# SCR_TC3xx register map
Vendor: Infineon; File version: 1.0
Registers are 8-bit, read-write, reset 0x0 unless marked. A register's access mark holds for its fields unless they carry their own. Offsets are from the block's base; [hi:lo] are bit positions; <NAME> marks a mode.

## SCR_UART — SCR Universal asynchronous receiver/transmitter (with LIN support)
Base 0x00040000
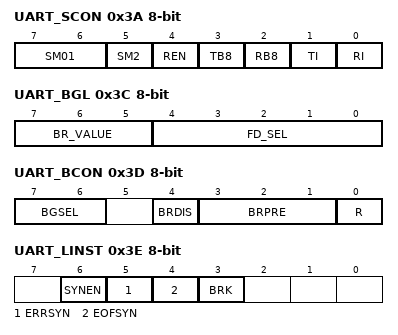
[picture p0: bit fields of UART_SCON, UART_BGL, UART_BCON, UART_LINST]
0x3A UART_SCON — Serial Channel Control Register (SFR 0xBA, RMAP 0)
  [7:6] SM01 — Serial Port Operating Mode Selection. Note:The operating mode of the UART must not be changed while bit REN is set or while a transmission is in progress. Before changing the mode of the UART, make sure that no transmissions are in progress, and that bit REN is cleared to 0. [rw]
    0=MODE_0 (8-bit shift register, fixed baud rate (fPCLK/2)); 1=MODE_1 (8-bit UART, variable baud rate); 2=MODE_2 (9-bit UART, fixed baud rate (fPCLK/64 or fPCLK/32)); 3=MODE_3 (9-bit UART, variable baud rate)
  [5] SM2 — Enable Serial Port Multiprocessor Communication in Modes 2 and 3. In mode 2 or 3, if SM2 is set to 1, RI will not be activated if the received 9th data bit (RB8) is 0. In mode 1, if SM2 is set to 1, RI will not be activated if a valid stop bit (RB8) was not received. In mode 0, SM2 should be 0. Note:The operating mode of the UART must not be changed while bit REN is set or while a transmission is in progress. Before changing the mode of the UART, make sure that no transmissions are in progress, and that bit REN is cleared to 0. [rw]
  [4] REN — Enable Receiver of Serial Port. Note:The operating mode of the UART must not be changed while bit REN is set (or while a transmission is in progress). Before changing the mode of the UART, bit REN shall be cleared to 0. [rw]
    0=SERIAL_RECEPTION_IS_DISABLED; 1=SERIAL_RECEPTION_IS_ENABLED
  [3] TB8 — Serial Port Transmitter Bit 9. In modes 2 and 3, this is the 9th data bit sent. [rw]
  [2] RB8 — Serial Port Receiver Bit 9. In modes 2 and 3, this is the 9th data bit received. In mode 1, this is the stop bit received. In mode 0, this bit is not used. [rwh]
  [1] TI — Transmit Interrupt Flag. This is set by hardware at the end of the 8th bit in mode 0, or at the beginning of the stop bit in modes 1, 2, and 3. This bit can also be set by software. Must be cleared by software. Note:If a transmission has been started and TI is still 0, a further write to UART_SBUF will destroy the ongoing transmission. If TI is set to 1, the next transmission can be started. [rwh]
  [0] RI — Receive Interrupt Flag. This is set by hardware at the end of the 8th bit on mode 0, or at the half point of the stop bit in modes 1, 2, and 3. This bit can also be set by software. Must be cleared by software. Note:In case of an ongoing reception and a mode change at the very same time, the flag RI will have an undefined behaviour, as it is dependent from the point in time of the mode change. [rwh]
0x3B UART_SBUF — Serial Data Buffer (SFR 0xBB, RMAP 0)
  [7:0] VAL — Serial Interface Buffer Register. [rwh]
0x3C UART_BGL — Baudrate Timer/Reload Register, Low Byte (SFR 0xBC, RMAP 0)
  [7:5] BR_VALUE — Baudrate Timer/Reload Value. The lower three bits of the 11-bit Baudrate Timer/Reload value. See also description in BGH register. Note:BR_VALUE shall be written if, and only if, BCON.R = 0. [rwh]
  [4:0] FD_SEL — Fractional Divider Selection. Selects the fractional divider to be n/32, where n is the value of FD_SEL, and is in the range of 0 to 31. For example, writing 0001B to FD_SEL selects the fractional divider to be 1/32. Note:Fractional divider has no effect if the 11-bit BR_VALUE = 000H. [rw]
0x3D UART_BCON — Baudrate Control Register (SFR 0xBD, RMAP 0)
  [7:6] BGSEL — Baudrate Select for Detection. For different values of BGSEL, the baud rate range for detection is defined by the following formula: fpclk/(2184*2^BGSEL) < baud rate range < fpclk/(74*2^BGSEL); where BGSEL = 00B, 01B, 10B, 11B. See table "BGSEL Bit Field Definition for Different Input Frequencies" for bit field BGSEL definition for different input frequencies. [rw]
  [4] BRDIS — Baudrate Detection Disable. Note:It is recommended to toggle bit BRDIS after the reception of each LIN frame (complete or erroneous frame) to avoid a wrong Break field detection in noisy environments (i.e. spikes on the LIN bus). [rw]
    0=BREAK_SYNC_DETECTION_IS_ENABLED; 1=BREAK_SYNC_DETECTION_IS_DISABLED
  [3:1] BRPRE — Prescaler Bit. Selects the input clock for fDIV, which is derived from the peripheral clock. others, Reserved [rw]
    0=DIV (fDIV = fPCLK); 1=DIV2 (fDIV = fPCLK / 2); 2=DIV4 (fDIV = fPCLK / 4); 3=DIV8 (fDIV = fPCLK / 8); 4=DIV16 (fDIV = fPCLK / 16); 5=DIV32 (fDIV = fPCLK / 32)
  [0] R — Baudrate Generator Run Control Bit. Note:BR_VALUE shall be written if, and only if, R = 0. [rw]
    0=BAUDRATE_GENERATOR_DISABLED; 1=BAUDRATE_GENERATOR_ENABLED
0x3E UART_LINST — LIN Status Register (SFR 0xBE, RMAP 0)
  [6] SYNEN — End of SYN Byte and SYN Byte Error Interrupts Enable. [rw]
    0=END_OF_SYN_BYTE_AND_SYN_BYTE (End of SYN Byte and SYN Byte Error Interrupts are not enabled); 1=END_OF_SYN_BYTE_AND_SYN_BYTE_2 (End of SYN Byte and SYN Byte Error Interrupts are enabled)
  [5] ERRSYN — SYN Byte Error Interrupt Flag. This bit is set by hardware and can only be cleared by software. [rwh]
    0=ERROR_IS_NOT_DETECTED_IN_SYN_BYTE; 1=ERROR_IS_DETECTED_IN_SYN_BYTE
  [4] EOFSYN — End of SYN Byte Interrupt Flag. This bit is set by hardware and can only be cleared by software. [rwh]
    0=END_OF_SYN_BYTE_IS_NOT_DETECTED; 1=END_OF_SYN_BYTE_IS_DETECTED
  [3] BRK — Break Field Flag. This bit is set by hardware and can only be cleared by software. [rwh]
    0=BREAK_FIELD_IS_NOT_DETECTED; 1=BREAK_FIELD_IS_DETECTED
0x3F UART_BGH — Baudrate Timer/Reload Register, High Byte (SFR 0xBF, RMAP 0)
  [7:0] BR_VALUE — Baudrate Timer/Reload Value. The upper 8 bits of the 11-bit Baudrate Timer/Reload value. When the 11-bit BR_VALUE is 000H, the baudrate timer is bypassed. Note:BR_VALUE shall be written if, and only if, BCON.R = 0. [rwh]
